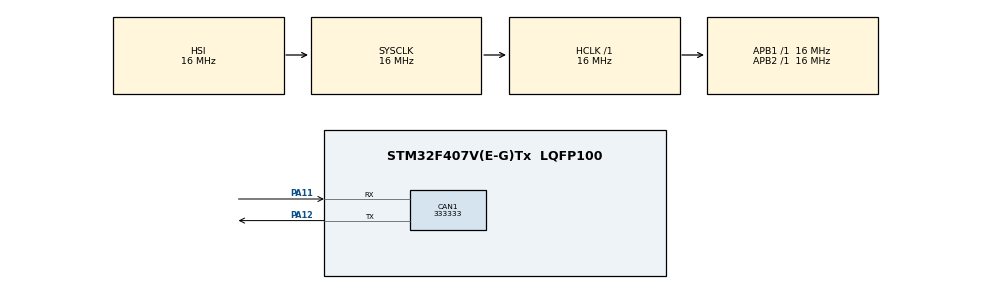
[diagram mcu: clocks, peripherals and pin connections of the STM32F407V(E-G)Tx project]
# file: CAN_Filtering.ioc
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CAN1.CalculateBaudRate=333333
CAN1.CalculateTimeBit=3000
CAN1.CalculateTimeQuantum=1000.0
Mcu.Family=STM32F4
Mcu.Name=STM32F407V(E-G)Tx
Mcu.Package=LQFP100
NVIC.PriorityGroup=NVIC_PRIORITYGROUP_4
PA11.Mode=CAN_Activate
PA11.Signal=CAN1_RX
PA12.Mode=CAN_Activate
PA12.Signal=CAN1_TX
ProjectManager.HeapSize=0x200
ProjectManager.StackSize=0x400
ProjectManager.TargetToolchain=STM32CubeIDE
RCC.AHBFreq_Value=16000000
RCC.APB1Freq_Value=16000000
RCC.APB2Freq_Value=16000000
RCC.CortexFreq_Value=16000000
RCC.HSE_VALUE=25000000
RCC.HSI_VALUE=16000000
RCC.LSE_VALUE=32768
RCC.SYSCLKFreq_VALUE=16000000
RCC.VCOOutputFreq_Value=192000000
board=custom

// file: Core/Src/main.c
/* USER CODE BEGIN Header */
/**
  ******************************************************************************
  * @file           : main.c
  * @brief          : Main program body
  ******************************************************************************
  * @attention
  *
  * Copyright (c) 2024 STMicroelectronics.
  * All rights reserved.
  *
  * This software is licensed under terms that can be found in the LICENSE file
  * in the root directory of this software component.
  * If no LICENSE file comes with this software, it is provided AS-IS.
  *
  ******************************************************************************
  */
/* USER CODE END Header */
#include "main.h"

CAN_HandleTypeDef hcan1;

/* USER CODE BEGIN PV */

CAN_TxHeaderTypeDef TxHeader;
CAN_RxHeaderTypeDef RxHeader;

uint32_t TxMailbox[4];

uint8_t TxData[8];
uint8_t RxData[8];

uint8_t count = 0;

void HAL_CAN_RxFifo0MsgPendingCallback(CAN_HandleTypeDef *hcan)
{
	HAL_CAN_GetRxMessage(hcan, CAN_RX_FIFO0, &RxHeader, RxData);
	if (RxHeader.StdId == 0x625) {
	    // Handle data for the expected message ID (0x100)
	    // Example: Print received data to serial console
	    printf("Received message with ID 0x625 and data: ");
	    for (int i = 0; i < RxHeader.DLC; ++i) {
	      printf("%02X ", RxData[i]);
	    }
	    printf("\n");
	}
	count++;
}

/* USER CODE END PV */

void SystemClock_Config(void);
static void MX_GPIO_Init(void);
static void MX_CAN1_Init(void);

int main(void)
{

  /* MCU Configuration--------------------------------------------------------*/

  /* Reset of all peripherals, Initializes the Flash interface and the Systick. */
  HAL_Init();

  /* USER CODE BEGIN Init */
	TxHeader.IDE = CAN_ID_STD;
	TxHeader.StdId = 0x1;
	TxHeader.RTR = CAN_RTR_DATA;
	TxHeader.DLC = 1;

	TxData[0] = count;

  /* USER CODE END Init */

  /* Configure the system clock */
  SystemClock_Config();

  /* Initialize all configured peripherals */
  MX_GPIO_Init();
  MX_CAN1_Init();
  /* USER CODE BEGIN 2 */

  HAL_CAN_Start(&hcan);

  HAL_CAN_ActivateNotification(&hcan, CAN_IT_RX_FIFO0_MSG_PENDING);

  if (HAL_CAN_AddTxMessage(&hcan, &TxHeader, &TxData[0], &TxMailbox[0]) != HAL_OK)
  {
	  Error_Handler();
  }
  if (HAL_CAN_AddTxMessage(&hcan, &TxHeader, &TxData[1], &TxMailbox[1]) != HAL_OK)
  {
	  Error_Handler();
  }
  if (HAL_CAN_AddTxMessage(&hcan, &TxHeader, &TxData[2], &TxMailbox[2]) != HAL_OK)
  {
	  Error_Handler();
  }

  if (HAL_CAN_AddTxMessage(&hcan, &TxHeader, &TxData[3], &TxMailbox[3]) != HAL_OK)
  {
	  Error_Handler();
  }

  /* USER CODE END 2 */

  /* Infinite loop */
  while (1)
  {

  }
}

void SystemClock_Config(void)
{
  RCC_OscInitTypeDef RCC_OscInitStruct = {0};
  RCC_ClkInitTypeDef RCC_ClkInitStruct = {0};

  /** Configure the main internal regulator output voltage
  */
  __HAL_RCC_PWR_CLK_ENABLE();
  __HAL_PWR_VOLTAGESCALING_CONFIG(PWR_REGULATOR_VOLTAGE_SCALE1);

  /** Initializes the RCC Oscillators according to the specified parameters
  * in the RCC_OscInitTypeDef structure.
  */
  RCC_OscInitStruct.OscillatorType = RCC_OSCILLATORTYPE_HSI;
  RCC_OscInitStruct.HSIState = RCC_HSI_ON;
  RCC_OscInitStruct.HSICalibrationValue = RCC_HSICALIBRATION_DEFAULT;
  RCC_OscInitStruct.PLL.PLLState = RCC_PLL_NONE;
  if (HAL_RCC_OscConfig(&RCC_OscInitStruct) != HAL_OK)
  {
    Error_Handler();
  }

  /** Initializes the CPU, AHB and APB buses clocks
  */
  RCC_ClkInitStruct.ClockType = RCC_CLOCKTYPE_HCLK|RCC_CLOCKTYPE_SYSCLK
                              |RCC_CLOCKTYPE_PCLK1|RCC_CLOCKTYPE_PCLK2;
  RCC_ClkInitStruct.SYSCLKSource = RCC_SYSCLKSOURCE_HSI;
  RCC_ClkInitStruct.AHBCLKDivider = RCC_SYSCLK_DIV1;
  RCC_ClkInitStruct.APB1CLKDivider = RCC_HCLK_DIV1;
  RCC_ClkInitStruct.APB2CLKDivider = RCC_HCLK_DIV1;

  if (HAL_RCC_ClockConfig(&RCC_ClkInitStruct, FLASH_LATENCY_0) != HAL_OK)
  {
    Error_Handler();
  }
}

static void MX_CAN1_Init(void)
{

  hcan1.Instance = CAN1;
  hcan1.Init.Prescaler = 16;
  hcan1.Init.Mode = CAN_MODE_NORMAL;
  hcan1.Init.SyncJumpWidth = CAN_SJW_1TQ;
  hcan1.Init.TimeSeg1 = CAN_BS1_1TQ;
  hcan1.Init.TimeSeg2 = CAN_BS2_1TQ;
  hcan1.Init.TimeTriggeredMode = DISABLE;
  hcan1.Init.AutoBusOff = DISABLE;
  hcan1.Init.AutoWakeUp = DISABLE;
  hcan1.Init.AutoRetransmission = DISABLE;
  hcan1.Init.ReceiveFifoLocked = DISABLE;
  hcan1.Init.TransmitFifoPriority = DISABLE;
  if (HAL_CAN_Init(&hcan1) != HAL_OK)
  {
    Error_Handler();
  }
  /* USER CODE BEGIN CAN1_Init 2 */

  CAN_FilterTypeDef canfilterconfig;

  //specifies whether filter should be enabled or disabled, enabled means
  // allows to actively filter incoming messages based on configurations
  canfilterconfig.FilterActivation = CAN_FILTER_ENABLE;
  // specifies which filter bank to use, filter banks are hardware resources
  // picked anything within 0-12, picked 12 for vibes
  canfilterconfig.FilterBank = 12;
  // picks which fifo buffer to direct messages to, send to 0 because
  // only have 1
  canfilterconfig.FilterFIFOAssignment = CAN_RX_FIFO0;
  // specifies id that incoming messages should match, shift by 5
  // shift by 5 to shift to the correct position in the corresponding register
  // ranges from standard (11-bit) to extended (29-bit)
  // identifier mode: both numbers are ids that should be caught
  canfilterconfig.FilterIdHigh = 0x625<<5;
  // using 625 because navya likes the number
  canfilterconfig.FilterIdLow = 0x625;
  // specify mask that bits are compared against, bits set to 1
  // need to match exactly, bits set to 0 should be ignored
  canfilterconfig.FilterMaskIdHigh = 0x1FFFFFFF;
  canfilterconfig.FilterMaskIdLow = 0x7FFF;
  canfilterconfig.FilterMode = CAN_FILTERMODE_IDMASK;
  canfilterconfig.FilterScale = CAN_FILTERSCALE_32BIT;
  canfilterconfig.SlaveStartFilterBank = 13;  // 13 to 27 are assigned to slave CAN (CAN 2) OR 0 to 12 are assgned to CAN1

  HAL_CAN_ConfigFilter(&hcan, &canfilterconfig);
  HAL_CAN_ActivateNotification(&hcan, CAN_IT_RX_FIFO0_MSG_PENDING);

  /* USER CODE END CAN1_Init 2 */

}

static void MX_GPIO_Init(void)
{

  /* GPIO Ports Clock Enable */
  __HAL_RCC_GPIOA_CLK_ENABLE();

}

void Error_Handler(void)
{
  __disable_irq();
  while (1)
  {
  }
}
